CM_ "IMPORT _honda_common.dbc";
CM_ "IMPORT _bosch_2018.dbc";
CM_ "IMPORT _lkas_hud_8byte.dbc";
CM_ "IMPORT _bosch_standstill.dbc";
CM_ "IMPORT _steering_sensors_a.dbc";
CM_ "IMPORT _gearbox_common.dbc";
CM_ "IMPORT _bosch_radarless_common.dbc";

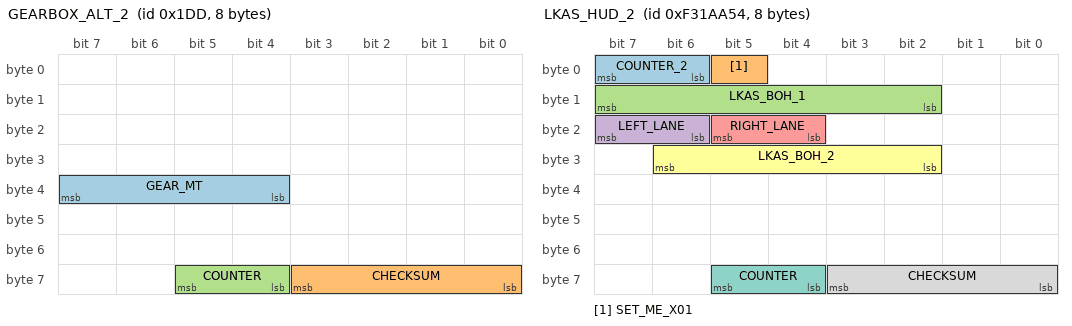
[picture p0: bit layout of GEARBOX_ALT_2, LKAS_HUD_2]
BO_ 477 GEARBOX_ALT_2: 8 XXX
 SG_ GEAR_MT : 39|4@0+ (1,0) [0|15] "" XXX
 SG_ CHECKSUM : 59|4@0+ (1,0) [0|15] "" XXX
 SG_ COUNTER : 61|2@0+ (1,0) [0|3] "" XXX

BO_ 254913108 LKAS_HUD_2: 8 ADAS
 SG_ COUNTER_2 : 7|2@0+ (1,0) [0|3] "" XXX
 SG_ SET_ME_X01 : 5|1@0+ (1,0) [0|1] "" XXX
 SG_ LKAS_BOH_1 : 15|6@0+ (1,0) [0|63] "" XXX
 SG_ LEFT_LANE : 23|2@0+ (1,0) [0|3] "" XXX
 SG_ RIGHT_LANE : 21|2@0+ (1,0) [0|3] "" XXX
 SG_ LKAS_BOH_2 : 30|5@0+ (1,0) [0|31] "" XXX
 SG_ COUNTER : 61|2@0+ (1,0) [0|3] "" XXX
 SG_ CHECKSUM : 59|4@0+ (1,0) [0|15] "" XXX

VAL_ 477 GEAR_MT 14 "reverse" 6 "6th" 5 "5th" 4 "4th" 3 "3rd" 2 "2nd" 1 "1st" 0 "Clutch";
